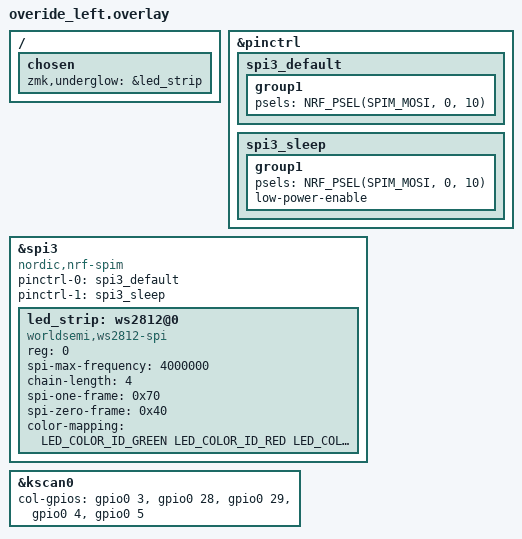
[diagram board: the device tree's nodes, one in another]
#include "overide.dtsi"
#include <dt-bindings/led/led.h>

&pinctrl {
    spi3_default: spi3_default {
        group1 {
            psels = <NRF_PSEL(SPIM_MOSI, 0, 10)>; // NFC2
        };
    };
    spi3_sleep: spi3_sleep {
        group1 {
            psels = <NRF_PSEL(SPIM_MOSI, 0, 10)>;
            low-power-enable;
        };
    };
};

&spi3 {
    compatible = "nordic,nrf-spim";
    status = "okay";
    pinctrl-0 = <&spi3_default>;
    pinctrl-1 = <&spi3_sleep>;
    pinctrl-names = "default", "sleep";

    led_strip: ws2812@0 {
        compatible = "worldsemi,ws2812-spi";
        reg = <0>;
        spi-max-frequency = <4000000>;
        chain-length = <4>;
        spi-one-frame = <0x70>;
        spi-zero-frame = <0x40>;
        color-mapping = <LED_COLOR_ID_GREEN LED_COLOR_ID_RED LED_COLOR_ID_BLUE>;
    };
};

/ {
    chosen {
        zmk,underglow = &led_strip;
    };
};

&kscan0 {
    col-gpios
        = <&gpio0 3  GPIO_ACTIVE_HIGH> // COL0 (A0)
        , <&gpio0 28 GPIO_ACTIVE_HIGH> // COL1 (A1)
        , <&gpio0 29 GPIO_ACTIVE_HIGH> // COL2 (A2)
        , <&gpio0 4  GPIO_ACTIVE_HIGH> // COL3 (A3)
        , <&gpio0 5  GPIO_ACTIVE_HIGH> // COL4 (A4)
        ;
};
